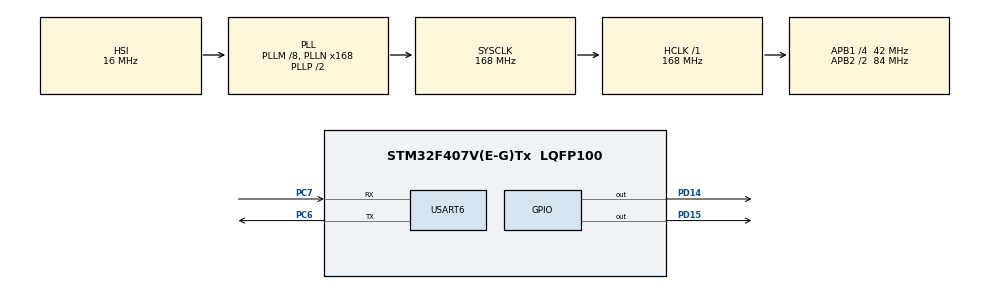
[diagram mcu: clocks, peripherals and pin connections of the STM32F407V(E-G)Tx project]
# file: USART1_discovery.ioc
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Mcu.Family=STM32F4
Mcu.Name=STM32F407V(E-G)Tx
Mcu.Package=LQFP100
NVIC.PriorityGroup=NVIC_PRIORITYGROUP_4
PC6.Mode=Asynchronous
PC6.Signal=USART6_TX
PC7.Mode=Asynchronous
PC7.Signal=USART6_RX
PD14.Signal=GPIO_Output
PD15.Signal=GPIO_Output
ProjectManager.HeapSize=0x200
ProjectManager.StackSize=0x400
ProjectManager.TargetToolchain=Other Toolchains (GPDSC)
RCC.48MHZClocksFreq_Value=84000000
RCC.AHBFreq_Value=168000000
RCC.APB1CLKDivider=RCC_HCLK_DIV4
RCC.APB1Freq_Value=42000000
RCC.APB1TimFreq_Value=84000000
RCC.APB2CLKDivider=RCC_HCLK_DIV2
RCC.APB2Freq_Value=84000000
RCC.APB2TimFreq_Value=168000000
RCC.CortexFreq_Value=168000000
RCC.HCLKFreq_Value=168000000
RCC.HSE_VALUE=8000000
RCC.HSI_VALUE=16000000
RCC.LSE_VALUE=32768
RCC.PLLM=8
RCC.PLLN=168
RCC.SYSCLKFreq_VALUE=168000000
RCC.SYSCLKSource=RCC_SYSCLKSOURCE_PLLCLK
RCC.VCOOutputFreq_Value=336000000
USART6.VirtualMode=VM_ASYNC
board=custom

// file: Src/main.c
/* USER CODE BEGIN Header */
/**
  ******************************************************************************
  * @file           : main.c
  * @brief          : Main program body
  ******************************************************************************
  ** This notice applies to any and all portions of this file
  * that are not between comment pairs USER CODE BEGIN and
  * USER CODE END. Other portions of this file, whether
  * inserted by the user or by software development tools
  * are owned by their respective copyright owners.
  *
  * COPYRIGHT(c) 2020 STMicroelectronics
  *
  * Redistribution and use in source and binary forms, with or without modification,
  * are permitted provided that the following conditions are met:
  *   1. Redistributions of source code must retain the above copyright notice,
  *      this list of conditions and the following disclaimer.
  *   2. Redistributions in binary form must reproduce the above copyright notice,
  *      this list of conditions and the following disclaimer in the documentation
  *      and/or other materials provided with the distribution.
  *   3. Neither the name of STMicroelectronics nor the names of its contributors
  *      may be used to endorse or promote products derived from this software
  *      without specific prior written permission.
  *
  * THIS SOFTWARE IS PROVIDED BY THE COPYRIGHT HOLDERS AND CONTRIBUTORS "AS IS"
  * AND ANY EXPRESS OR IMPLIED WARRANTIES, INCLUDING, BUT NOT LIMITED TO, THE
  * IMPLIED WARRANTIES OF MERCHANTABILITY AND FITNESS FOR A PARTICULAR PURPOSE ARE
  * DISCLAIMED. IN NO EVENT SHALL THE COPYRIGHT HOLDER OR CONTRIBUTORS BE LIABLE
  * FOR ANY DIRECT, INDIRECT, INCIDENTAL, SPECIAL, EXEMPLARY, OR CONSEQUENTIAL
  * DAMAGES (INCLUDING, BUT NOT LIMITED TO, PROCUREMENT OF SUBSTITUTE GOODS OR
  * SERVICES; LOSS OF USE, DATA, OR PROFITS; OR BUSINESS INTERRUPTION) HOWEVER
  * CAUSED AND ON ANY THEORY OF LIABILITY, WHETHER IN CONTRACT, STRICT LIABILITY,
  * OR TORT (INCLUDING NEGLIGENCE OR OTHERWISE) ARISING IN ANY WAY OUT OF THE USE
  * OF THIS SOFTWARE, EVEN IF ADVISED OF THE POSSIBILITY OF SUCH DAMAGE.
  *
  ******************************************************************************
  */
/* USER CODE END Header */

#include "main.h"

/* USER CODE BEGIN Includes */
#include "stdio.h"
/* USER CODE END Includes */

UART_HandleTypeDef huart6;

/* USER CODE BEGIN PV */
uint8_t RX[40], TX[40], num=0, tam=0;
/* USER CODE END PV */

void SystemClock_Config(void);
static void MX_GPIO_Init(void);
static void MX_USART6_UART_Init(void);

int main(void)
{

  /* MCU Configuration--------------------------------------------------------*/

  /* Reset of all peripherals, Initializes the Flash interface and the Systick. */
  HAL_Init();

  /* Configure the system clock */
  SystemClock_Config();

  /* Initialize all configured peripherals */
  MX_GPIO_Init();
  MX_USART6_UART_Init();

  /* Infinite loop */
  /* USER CODE BEGIN WHILE */
  while (1)
  {
    HAL_UART_Receive(&huart6, RX, 1, 10);

    tam = sprintf(TX,"%u \r\n",num);
    HAL_UART_Transmit(&huart6, TX, tam, 10);
    num++;

    if(RX[0] == 'A'){
      HAL_GPIO_WritePin(GPIOD, GPIO_PIN_15, GPIO_PIN_SET);
    }
    if(RX[0] == 'B'){
      HAL_GPIO_WritePin(GPIOD, GPIO_PIN_15, GPIO_PIN_RESET);
    }

    HAL_GPIO_TogglePin(GPIOD, GPIO_PIN_14);
    HAL_Delay(100);

    /* USER CODE END WHILE */

  }
}

void SystemClock_Config(void)
{
  RCC_OscInitTypeDef RCC_OscInitStruct = {0};
  RCC_ClkInitTypeDef RCC_ClkInitStruct = {0};

  /**Configure the main internal regulator output voltage
  */
  __HAL_RCC_PWR_CLK_ENABLE();
  __HAL_PWR_VOLTAGESCALING_CONFIG(PWR_REGULATOR_VOLTAGE_SCALE1);
  /**Initializes the CPU, AHB and APB busses clocks
  */
  RCC_OscInitStruct.OscillatorType = RCC_OSCILLATORTYPE_HSI;
  RCC_OscInitStruct.HSIState = RCC_HSI_ON;
  RCC_OscInitStruct.HSICalibrationValue = RCC_HSICALIBRATION_DEFAULT;
  RCC_OscInitStruct.PLL.PLLState = RCC_PLL_ON;
  RCC_OscInitStruct.PLL.PLLSource = RCC_PLLSOURCE_HSI;
  RCC_OscInitStruct.PLL.PLLM = 8;
  RCC_OscInitStruct.PLL.PLLN = 168;
  RCC_OscInitStruct.PLL.PLLP = RCC_PLLP_DIV2;
  RCC_OscInitStruct.PLL.PLLQ = 4;
  if (HAL_RCC_OscConfig(&RCC_OscInitStruct) != HAL_OK)
  {
    Error_Handler();
  }
  /**Initializes the CPU, AHB and APB busses clocks
  */
  RCC_ClkInitStruct.ClockType = RCC_CLOCKTYPE_HCLK|RCC_CLOCKTYPE_SYSCLK
                              |RCC_CLOCKTYPE_PCLK1|RCC_CLOCKTYPE_PCLK2;
  RCC_ClkInitStruct.SYSCLKSource = RCC_SYSCLKSOURCE_PLLCLK;
  RCC_ClkInitStruct.AHBCLKDivider = RCC_SYSCLK_DIV1;
  RCC_ClkInitStruct.APB1CLKDivider = RCC_HCLK_DIV4;
  RCC_ClkInitStruct.APB2CLKDivider = RCC_HCLK_DIV2;

  if (HAL_RCC_ClockConfig(&RCC_ClkInitStruct, FLASH_LATENCY_5) != HAL_OK)
  {
    Error_Handler();
  }
}

static void MX_USART6_UART_Init(void)
{

  huart6.Instance = USART6;
  huart6.Init.BaudRate = 115200;
  huart6.Init.WordLength = UART_WORDLENGTH_8B;
  huart6.Init.StopBits = UART_STOPBITS_1;
  huart6.Init.Parity = UART_PARITY_NONE;
  huart6.Init.Mode = UART_MODE_TX_RX;
  huart6.Init.HwFlowCtl = UART_HWCONTROL_NONE;
  huart6.Init.OverSampling = UART_OVERSAMPLING_16;
  if (HAL_UART_Init(&huart6) != HAL_OK)
  {
    Error_Handler();
  }

}

static void MX_GPIO_Init(void)
{
  GPIO_InitTypeDef GPIO_InitStruct = {0};

  /* GPIO Ports Clock Enable */
  __HAL_RCC_GPIOD_CLK_ENABLE();
  __HAL_RCC_GPIOC_CLK_ENABLE();

  /*Configure GPIO pin Output Level */
  HAL_GPIO_WritePin(GPIOD, GPIO_PIN_14|GPIO_PIN_15, GPIO_PIN_RESET);

  /*Configure GPIO pins : PD14 PD15 */
  GPIO_InitStruct.Pin = GPIO_PIN_14|GPIO_PIN_15;
  GPIO_InitStruct.Mode = GPIO_MODE_OUTPUT_PP;
  GPIO_InitStruct.Pull = GPIO_NOPULL;
  GPIO_InitStruct.Speed = GPIO_SPEED_FREQ_LOW;
  HAL_GPIO_Init(GPIOD, &GPIO_InitStruct);

}

void Error_Handler(void)
{
}

/************************ (C) COPYRIGHT STMicroelectronics *****END OF FILE****/
